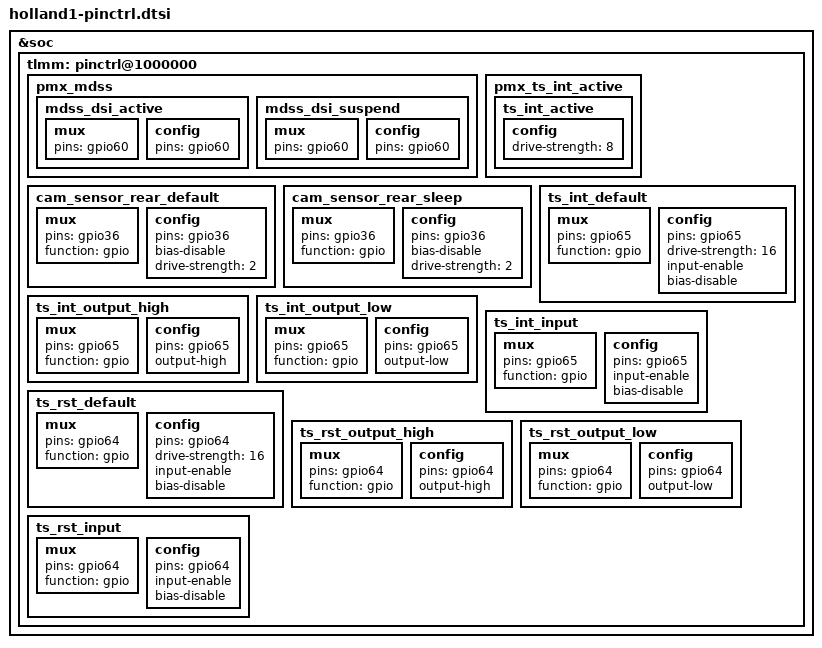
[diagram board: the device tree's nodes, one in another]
/* Copyright (c) 2020, The Linux Foundation. All rights reserved.
*  Copyright (c) 2020, Jebaitedneko.
*
* This program is free software; you can redistribute it and/or modify
* it under the terms of the GNU General Public License version 2 and
* only version 2 as published by the Free Software Foundation.
*
* This program is distributed in the hope that it will be useful,
* but WITHOUT ANY WARRANTY; without even the implied warranty of
* MERCHANTABILITY or FITNESS FOR A PARTICULAR PURPOSE.  See the
* GNU General Public License for more details.
*/

&soc {

	tlmm: pinctrl@1000000 {

		pmx_mdss: pmx_mdss {

			mdss_dsi_active: mdss_dsi_active {

				mux {

					pins = "gpio60";
				};

				config {

					pins = "gpio60";
				};
			};

			mdss_dsi_suspend: mdss_dsi_suspend {

				mux {

					pins = "gpio60";
				};

				config {

					pins = "gpio60";
				};
			};
		};

		/* add pingrp for touchscreen */

		pmx_ts_int_active {

			ts_int_active: ts_int_active {

				config {

					drive-strength = <8>;
				};
			};
		};

		cam_sensor_rear_default: cam_sensor_rear_default {
			/* RESET, STANDBY */
			mux {
				pins = "gpio36";
				function = "gpio";
			};

			config {
				pins = "gpio36";
				bias-disable; /* No PULL */
				drive-strength = <2>; /* 2 MA */
			};
		};

		cam_sensor_rear_sleep: cam_sensor_rear_sleep {
			/* RESET, STANDBY */
			mux {
				pins = "gpio36";
				function = "gpio";
			};

			config {
				pins = "gpio36";
				bias-disable; /* No PULL */
				drive-strength = <2>; /* 2 MA */
			};
		};

		/* add pingrp for goodix touch */
		ts_int_default: ts_int_default {
			mux {
				pins = "gpio65";
				function = "gpio";
			};
			config {
				pins = "gpio65";
				drive-strength = <16>;
				/*bias-pull-up;*/
				input-enable;
				bias-disable;
			};
		};

		ts_int_output_high: ts_int_output_high {
			mux {
				pins = "gpio65";
				function = "gpio";
			};
			config {
				pins = "gpio65";
				output-high;
			};
		};

		ts_int_output_low: ts_int_output_low {
			mux {
				pins = "gpio65";
				function = "gpio";
			};
			config {
				pins = "gpio65";
				output-low;
			};
		};

		ts_int_input: ts_int_input {
			mux {
				pins = "gpio65";
				function = "gpio";
			};
			config {
				pins = "gpio65";
				input-enable;
				bias-disable;
			};
		};

		ts_rst_default: ts_rst_default {
			mux {
				pins = "gpio64";
				function = "gpio";
			};
			config {
				pins = "gpio64";
				drive-strength = <16>;
				/*bias-pull-up;*/
				input-enable;
				bias-disable;
			};
		};

		ts_rst_output_high: ts_rst_output_high {
			mux {
				pins = "gpio64";
				function = "gpio";
			};
			config {
				pins = "gpio64";
				output-high;
			};
		};

		ts_rst_output_low: ts_rst_output_low {
			mux {
				pins = "gpio64";
				function = "gpio";
			};
			config {
				pins = "gpio64";
				output-low;
			};
		};

		ts_rst_input: ts_rst_input {
			mux {
				pins = "gpio64";
				function = "gpio";
			};
			config {
				pins = "gpio64";
				input-enable;
				bias-disable;
			};
		};
	};
};
